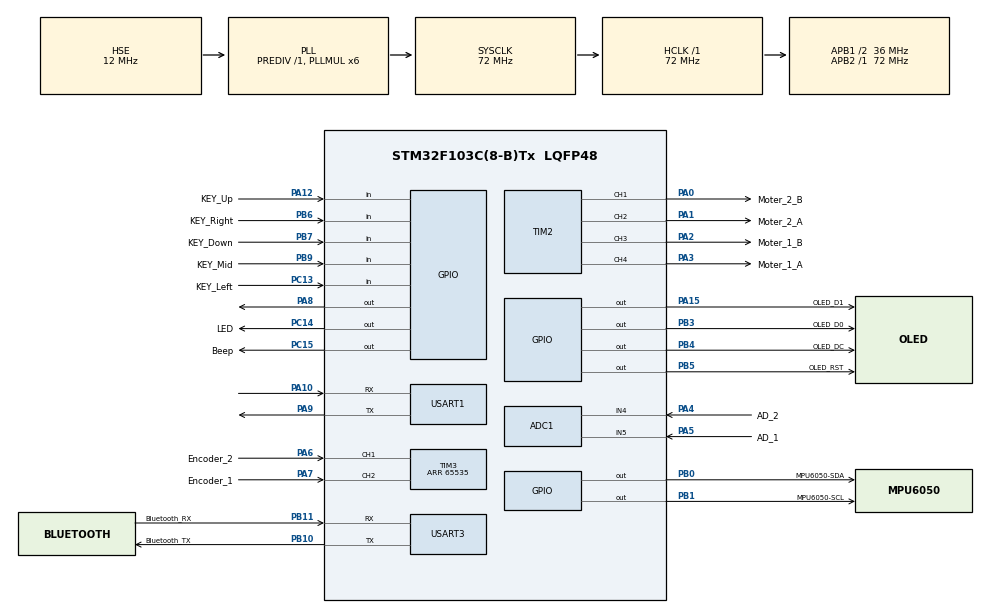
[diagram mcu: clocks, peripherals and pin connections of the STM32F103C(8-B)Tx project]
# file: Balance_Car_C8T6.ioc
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ADC1.Channel-298\#ChannelRegularConversion=ADC_CHANNEL_4
ADC1.ContinuousConvMode=DISABLE
ADC1.DataAlign=ADC_DATAALIGN_RIGHT
ADC1.DiscontinuousConvMode=DISABLE
ADC1.EnableAnalogWatchDog=false
ADC1.EnableRegularConversion=ENABLE
ADC1.ExternalTrigConv=ADC_SOFTWARE_START
ADC1.InjNumberOfConversion=0
ADC1.NbrOfConversion=1
ADC1.NbrOfConversionFlag=1
ADC1.Rank-298\#ChannelRegularConversion=1
ADC1.SamplingTime-298\#ChannelRegularConversion=ADC_SAMPLETIME_1CYCLE_5
ADC1.ScanConvMode=ADC_SCAN_DISABLE
ADC1.master=1
Mcu.Family=STM32F1
Mcu.Name=STM32F103C(8-B)Tx
Mcu.Package=LQFP48
NVIC.PriorityGroup=NVIC_PRIORITYGROUP_4
PA0-WKUP.GPIO_Label=Moter_2_B
PA0-WKUP.Signal=S_TIM2_CH1_ETR
PA1.GPIO_Label=Moter_2_A
PA1.Signal=S_TIM2_CH2
PA10.Mode=Asynchronous
PA10.Signal=USART1_RX
PA12.GPIO_Label=KEY_Up
PA12.GPIO_PuPd=GPIO_PULLUP
PA12.Signal=GPIO_Input
PA13.Mode=Serial_Wire
PA13.Signal=SYS_JTMS-SWDIO
PA14.Mode=Serial_Wire
PA14.Signal=SYS_JTCK-SWCLK
PA15.GPIO_Label=OLED_D1
PA15.Signal=GPIO_Output
PA2.GPIO_Label=Moter_1_B
PA2.Signal=S_TIM2_CH3
PA3.GPIO_Label=Moter_1_A
PA3.Signal=S_TIM2_CH4
PA4.GPIO_Label=AD_2
PA4.Signal=ADCx_IN4
PA5.GPIO_Label=AD_1
PA5.Signal=ADCx_IN5
PA6.GPIO_Label=Encoder_2
PA6.Signal=S_TIM3_CH1
PA7.GPIO_Label=Encoder_1
PA7.Signal=S_TIM3_CH2
PA8.Signal=GPIO_Output
PA9.Mode=Asynchronous
PA9.Signal=USART1_TX
PB0.GPIO_Label=MPU6050-SDA
PB0.Signal=GPIO_Output
PB1.GPIO_Label=MPU6050-SCL
PB1.Signal=GPIO_Output
PB10.GPIO_Label=Bluetooth_TX
PB10.Mode=Asynchronous
PB10.Signal=USART3_TX
PB11.GPIO_Label=Bluetooth_RX
PB11.Mode=Asynchronous
PB11.Signal=USART3_RX
PB3.GPIO_Label=OLED_D0
PB3.Signal=GPIO_Output
PB4.GPIO_Label=OLED_DC
PB4.Signal=GPIO_Output
PB5.GPIO_Label=OLED_RST
PB5.Signal=GPIO_Output
PB6.GPIO_Label=KEY_Right
PB6.GPIO_PuPd=GPIO_PULLUP
PB6.Signal=GPIO_Input
PB7.GPIO_Label=KEY_Down
PB7.GPIO_PuPd=GPIO_PULLUP
PB7.Signal=GPIO_Input
PB9.GPIO_Label=KEY_Mid
PB9.GPIO_PuPd=GPIO_PULLUP
PB9.Signal=GPIO_Input
PC13-TAMPER-RTC.GPIO_Label=KEY_Left
PC13-TAMPER-RTC.Signal=GPIO_Input
PC14-OSC32_IN.GPIO_Label=LED
PC14-OSC32_IN.GPIO_Speed=GPIO_SPEED_FREQ_HIGH
PC14-OSC32_IN.PinState=GPIO_PIN_SET
PC14-OSC32_IN.Signal=GPIO_Output
PC15-OSC32_OUT.GPIO_Label=Beep
PC15-OSC32_OUT.GPIO_Speed=GPIO_SPEED_FREQ_HIGH
PC15-OSC32_OUT.PinState=GPIO_PIN_SET
PC15-OSC32_OUT.Signal=GPIO_Output
PD0-OSC_IN.Mode=HSE-External-Oscillator
PD0-OSC_IN.Signal=RCC_OSC_IN
PD1-OSC_OUT.Mode=HSE-External-Oscillator
PD1-OSC_OUT.Signal=RCC_OSC_OUT
ProjectManager.HeapSize=0x200
ProjectManager.StackSize=0x400
ProjectManager.TargetToolchain=MDK-ARM V5
RCC.ADCPresc=RCC_ADCPCLK2_DIV6
RCC.AHBFreq_Value=72000000
RCC.APB1CLKDivider=RCC_HCLK_DIV2
RCC.APB1Freq_Value=36000000
RCC.APB1TimFreq_Value=72000000
RCC.APB2Freq_Value=72000000
RCC.APB2TimFreq_Value=72000000
RCC.HCLKFreq_Value=72000000
RCC.HSE_VALUE=12000000
RCC.PLLMUL=RCC_PLL_MUL6
RCC.PLLSourceVirtual=RCC_PLLSOURCE_HSE
RCC.SYSCLKFreq_VALUE=72000000
RCC.SYSCLKSource=RCC_SYSCLKSOURCE_PLLCLK
RCC.USBFreq_Value=72000000
SH.ADCx_IN4.0=ADC1_IN4,IN4
SH.ADCx_IN5.0=ADC1_IN5,IN5
SH.S_TIM2_CH1_ETR.0=TIM2_CH1,PWM Generation1 CH1
SH.S_TIM2_CH2.0=TIM2_CH2,PWM Generation2 CH2
SH.S_TIM2_CH3.0=TIM2_CH3,PWM Generation3 CH3
SH.S_TIM2_CH4.0=TIM2_CH4,PWM Generation4 CH4
SH.S_TIM3_CH1.0=TIM3_CH1,Encoder_Interface
SH.S_TIM3_CH2.0=TIM3_CH2,Encoder_Interface
TIM2.Channel-PWM\ Generation1\ CH1=TIM_CHANNEL_1
TIM2.Channel-PWM\ Generation2\ CH2=TIM_CHANNEL_2
TIM2.Channel-PWM\ Generation3\ CH3=TIM_CHANNEL_3
TIM2.Channel-PWM\ Generation4\ CH4=TIM_CHANNEL_4
TIM3.AutoReloadPreload=TIM_AUTORELOAD_PRELOAD_DISABLE
TIM3.EncoderMode=TIM_ENCODERMODE_TI12
TIM3.Period=65535
USART1.VirtualMode=VM_ASYNC
USART3.VirtualMode=VM_ASYNC
board=Balance_Car_C8T6

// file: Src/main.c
/**
  ******************************************************************************
  * File Name          : main.c
  * Description        : Main program body
  ******************************************************************************
  ** This notice applies to any and all portions of this file
  * that are not between comment pairs USER CODE BEGIN and
  * USER CODE END. Other portions of this file, whether
  * inserted by the user or by software development tools
  * are owned by their respective copyright owners.
  *
  * COPYRIGHT(c) 2017 STMicroelectronics
  *
  * Redistribution and use in source and binary forms, with or without modification,
  * are permitted provided that the following conditions are met:
  *   1. Redistributions of source code must retain the above copyright notice,
  *      this list of conditions and the following disclaimer.
  *   2. Redistributions in binary form must reproduce the above copyright notice,
  *      this list of conditions and the following disclaimer in the documentation
  *      and/or other materials provided with the distribution.
  *   3. Neither the name of STMicroelectronics nor the names of its contributors
  *      may be used to endorse or promote products derived from this software
  *      without specific prior written permission.
  *
  * THIS SOFTWARE IS PROVIDED BY THE COPYRIGHT HOLDERS AND CONTRIBUTORS "AS IS"
  * AND ANY EXPRESS OR IMPLIED WARRANTIES, INCLUDING, BUT NOT LIMITED TO, THE
  * IMPLIED WARRANTIES OF MERCHANTABILITY AND FITNESS FOR A PARTICULAR PURPOSE ARE
  * DISCLAIMED. IN NO EVENT SHALL THE COPYRIGHT HOLDER OR CONTRIBUTORS BE LIABLE
  * FOR ANY DIRECT, INDIRECT, INCIDENTAL, SPECIAL, EXEMPLARY, OR CONSEQUENTIAL
  * DAMAGES (INCLUDING, BUT NOT LIMITED TO, PROCUREMENT OF SUBSTITUTE GOODS OR
  * SERVICES; LOSS OF USE, DATA, OR PROFITS; OR BUSINESS INTERRUPTION) HOWEVER
  * CAUSED AND ON ANY THEORY OF LIABILITY, WHETHER IN CONTRACT, STRICT LIABILITY,
  * OR TORT (INCLUDING NEGLIGENCE OR OTHERWISE) ARISING IN ANY WAY OUT OF THE USE
  * OF THIS SOFTWARE, EVEN IF ADVISED OF THE POSSIBILITY OF SUCH DAMAGE.
  *
  ******************************************************************************
  */
#include "main.h"
#include "stm32f1xx_hal.h"
#include "adc.h"
#include "tim.h"
#include "usart.h"
#include "gpio.h"

/* USER CODE BEGIN Includes */
#include "oled.h"
#include "UI.h"
/* USER CODE END Includes */

/* USER CODE BEGIN PV */
/* Private variables ---------------------------------------------------------*/

/* USER CODE END PV */

void SystemClock_Config(void);

/* USER CODE BEGIN PFP */
/* Private function prototypes -----------------------------------------------*/

/* USER CODE END PFP */

int main(void)
{

  /* MCU Configuration----------------------------------------------------------*/

  /* Reset of all peripherals, Initializes the Flash interface and the Systick. */
  HAL_Init();

  /* Configure the system clock */
  SystemClock_Config();

  /* Initialize all configured peripherals */
  MX_GPIO_Init();
  MX_TIM2_Init();
  MX_USART1_UART_Init();
  MX_USART3_UART_Init();
  MX_ADC1_Init();
  MX_TIM3_Init();

  /* USER CODE BEGIN 2 */
  /* USER CODE BEGIN 1 */

	OLED_Init();

	uint8_t GO = 0;

  /* USER CODE END 2 */

  /* Infinite loop */
  while (1)
  {

  /* USER CODE BEGIN 3 */

//		Get_Key();
//		HAL_Delay(500);
		HAL_GPIO_WritePin(GPIOC, Beep_Pin, GPIO_PIN_RESET);
		HAL_GPIO_WritePin(GPIOC, LED_Pin, GPIO_PIN_RESET);
		HAL_GPIO_WritePin(GPIOA, GPIO_PIN_8, GPIO_PIN_RESET);
//		HAL_Delay(500);
//		HAL_GPIO_WritePin(GPIOC, Beep_Pin, GPIO_PIN_SET);
//		HAL_GPIO_WritePin(GPIOC, LED_Pin, GPIO_PIN_SET);
//		HAL_GPIO_WritePin(GPIOA, GPIO_PIN_8, GPIO_PIN_SET);
//		switch (GO)
//		{
//		case  0:	GO = Main_UI_Con();		break;//���˵�
//		case  1:	GO = Fun1_UI_Con();		break;
//		case  2:	GO = Fun2_UI_Con();		break;
//		case  3:	GO = Fun3_UI_Con();		break;
//		case  4:	GO = Fun4_UI_Con();		break;

//		default: 	GO = Main_UI_Con();		break;
//		}
//	if��HAL_ADC_Start����AdcHandle����= HAL_OK��
//	{
//		Error_Handler����;
//	}
//	HAL_ADC_PollForConversion����AdcHandle��10��;

//	if��HAL_ADC_GetState����AdcHandle��== HAL_ADC_STATE_EOC_REG��
//	{
//		uhADCxConvertedValue = HAL_ADC_GetValue����AdcHandle��;
//	}
//		Get_Key();
//
//		ADC_Enable(&hadc1);

//		HAL_ADC_Start(&hadc1);
//		HAL_ADC_PollForConversion(&hadc1, 10);
//		int i;
//		uint8_t ch[20];

//			i = HAL_ADC_GetValue(&hadc1);

//		sprintf(ch, "ADC:%d", i);
//		OLED_ShowString_Normal(0, 26, ch, 12);
//		OLED_Refresh_Gram();
  }
  /* USER CODE END 3 */

}

/** System Clock Configuration
*/
void SystemClock_Config(void)
{

  RCC_OscInitTypeDef RCC_OscInitStruct;
  RCC_ClkInitTypeDef RCC_ClkInitStruct;
  RCC_PeriphCLKInitTypeDef PeriphClkInit;

    /**Initializes the CPU, AHB and APB busses clocks
    */
  RCC_OscInitStruct.OscillatorType = RCC_OSCILLATORTYPE_HSE;
  RCC_OscInitStruct.HSEState = RCC_HSE_ON;
  RCC_OscInitStruct.HSEPredivValue = RCC_HSE_PREDIV_DIV1;
  RCC_OscInitStruct.HSIState = RCC_HSI_ON;
  RCC_OscInitStruct.PLL.PLLState = RCC_PLL_ON;
  RCC_OscInitStruct.PLL.PLLSource = RCC_PLLSOURCE_HSE;
  RCC_OscInitStruct.PLL.PLLMUL = RCC_PLL_MUL6;
  if (HAL_RCC_OscConfig(&RCC_OscInitStruct) != HAL_OK)
  {
    _Error_Handler(__FILE__, __LINE__);
  }

    /**Initializes the CPU, AHB and APB busses clocks
    */
  RCC_ClkInitStruct.ClockType = RCC_CLOCKTYPE_HCLK|RCC_CLOCKTYPE_SYSCLK
                              |RCC_CLOCKTYPE_PCLK1|RCC_CLOCKTYPE_PCLK2;
  RCC_ClkInitStruct.SYSCLKSource = RCC_SYSCLKSOURCE_PLLCLK;
  RCC_ClkInitStruct.AHBCLKDivider = RCC_SYSCLK_DIV1;
  RCC_ClkInitStruct.APB1CLKDivider = RCC_HCLK_DIV2;
  RCC_ClkInitStruct.APB2CLKDivider = RCC_HCLK_DIV1;

  if (HAL_RCC_ClockConfig(&RCC_ClkInitStruct, FLASH_LATENCY_2) != HAL_OK)
  {
    _Error_Handler(__FILE__, __LINE__);
  }

  PeriphClkInit.PeriphClockSelection = RCC_PERIPHCLK_ADC;
  PeriphClkInit.AdcClockSelection = RCC_ADCPCLK2_DIV6;
  if (HAL_RCCEx_PeriphCLKConfig(&PeriphClkInit) != HAL_OK)
  {
    _Error_Handler(__FILE__, __LINE__);
  }

    /**Configure the Systick interrupt time
    */
  HAL_SYSTICK_Config(HAL_RCC_GetHCLKFreq()/1000);

    /**Configure the Systick
    */
  HAL_SYSTICK_CLKSourceConfig(SYSTICK_CLKSOURCE_HCLK);

  /* SysTick_IRQn interrupt configuration */
  HAL_NVIC_SetPriority(SysTick_IRQn, 0, 0);
}

void _Error_Handler(char * file, int line)
{
  while(1)
  {
  }
}

/************************ (C) COPYRIGHT STMicroelectronics *****END OF FILE****/
